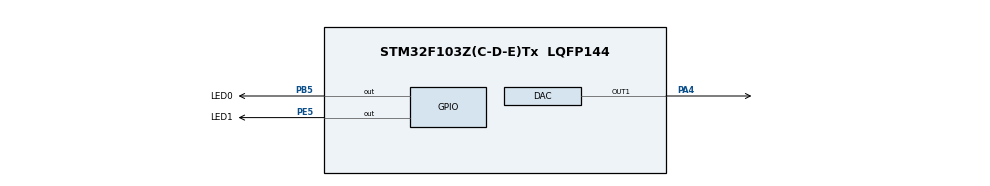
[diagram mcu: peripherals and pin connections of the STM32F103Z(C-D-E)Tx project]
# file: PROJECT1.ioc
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Mcu.Family=STM32F1
Mcu.Name=STM32F103Z(C-D-E)Tx
Mcu.Package=LQFP144
NVIC.PriorityGroup=NVIC_PRIORITYGROUP_4
PA4.Signal=COMP_DAC1_group
PB5.GPIO_Label=LED0
PB5.GPIO_ModeDefaultOutputPP=GPIO_MODE_OUTPUT_PP
PB5.GPIO_PuPd=GPIO_NOPULL
PB5.GPIO_Speed=GPIO_SPEED_FREQ_HIGH
PB5.PinState=GPIO_PIN_SET
PB5.Signal=GPIO_Output
PE5.GPIO_Label=LED1
PE5.GPIO_ModeDefaultOutputPP=GPIO_MODE_OUTPUT_PP
PE5.GPIO_PuPd=GPIO_NOPULL
PE5.GPIO_Speed=GPIO_SPEED_FREQ_HIGH
PE5.PinState=GPIO_PIN_SET
PE5.Signal=GPIO_Output
ProjectManager.HeapSize=0x200
ProjectManager.StackSize=0x400
ProjectManager.TargetToolchain=MDK-ARM V5.32
RCC.APB1Freq_Value=8000000
RCC.APB2Freq_Value=8000000
SH.COMP_DAC1_group.0=DAC_OUT1,DAC_OUT1
VP_SYS_VS_ND.Mode=No_Debug
board=custom

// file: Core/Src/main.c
/* USER CODE BEGIN Header */
/**
  ******************************************************************************
  * @file           : main.c
  * @brief          : Main program body
  ******************************************************************************
  * @attention
  *
  * Copyright (c) 2024 STMicroelectronics.
  * All rights reserved.
  *
  * This software is licensed under terms that can be found in the LICENSE file
  * in the root directory of this software component.
  * If no LICENSE file comes with this software, it is provided AS-IS.
  *
  ******************************************************************************
  */
/* USER CODE END Header */
#include "main.h"

DAC_HandleTypeDef hdac;

void SystemClock_Config(void);
static void MX_GPIO_Init(void);
static void MX_DAC_Init(void);

int main(void)
{

  /* MCU Configuration--------------------------------------------------------*/

  /* Reset of all peripherals, Initializes the Flash interface and the Systick. */
  HAL_Init();

  /* Configure the system clock */
  SystemClock_Config();

  /* Initialize all configured peripherals */
  MX_GPIO_Init();
  MX_DAC_Init();

  /* Infinite loop */
  /* USER CODE BEGIN WHILE */
  while (1)
  {
				HAL_GPIO_WritePin(LED0_GPIO_Port,LED0_Pin,GPIO_PIN_RESET);
				HAL_GPIO_WritePin(LED1_GPIO_Port,LED1_Pin,GPIO_PIN_RESET);

    /* USER CODE END WHILE */

  }
}

void SystemClock_Config(void)
{
  RCC_OscInitTypeDef RCC_OscInitStruct = {0};
  RCC_ClkInitTypeDef RCC_ClkInitStruct = {0};

  /** Initializes the RCC Oscillators according to the specified parameters
  * in the RCC_OscInitTypeDef structure.
  */
  RCC_OscInitStruct.OscillatorType = RCC_OSCILLATORTYPE_HSI;
  RCC_OscInitStruct.HSIState = RCC_HSI_ON;
  RCC_OscInitStruct.HSICalibrationValue = RCC_HSICALIBRATION_DEFAULT;
  RCC_OscInitStruct.PLL.PLLState = RCC_PLL_NONE;
  if (HAL_RCC_OscConfig(&RCC_OscInitStruct) != HAL_OK)
  {
    Error_Handler();
  }

  /** Initializes the CPU, AHB and APB buses clocks
  */
  RCC_ClkInitStruct.ClockType = RCC_CLOCKTYPE_HCLK|RCC_CLOCKTYPE_SYSCLK
                              |RCC_CLOCKTYPE_PCLK1|RCC_CLOCKTYPE_PCLK2;
  RCC_ClkInitStruct.SYSCLKSource = RCC_SYSCLKSOURCE_HSI;
  RCC_ClkInitStruct.AHBCLKDivider = RCC_SYSCLK_DIV1;
  RCC_ClkInitStruct.APB1CLKDivider = RCC_HCLK_DIV1;
  RCC_ClkInitStruct.APB2CLKDivider = RCC_HCLK_DIV1;

  if (HAL_RCC_ClockConfig(&RCC_ClkInitStruct, FLASH_LATENCY_0) != HAL_OK)
  {
    Error_Handler();
  }
}

static void MX_DAC_Init(void)
{

  DAC_ChannelConfTypeDef sConfig = {0};

  /** DAC Initialization
  */
  hdac.Instance = DAC;
  if (HAL_DAC_Init(&hdac) != HAL_OK)
  {
    Error_Handler();
  }

  /** DAC channel OUT1 config
  */
  sConfig.DAC_Trigger = DAC_TRIGGER_NONE;
  sConfig.DAC_OutputBuffer = DAC_OUTPUTBUFFER_ENABLE;
  if (HAL_DAC_ConfigChannel(&hdac, &sConfig, DAC_CHANNEL_1) != HAL_OK)
  {
    Error_Handler();
  }

}

static void MX_GPIO_Init(void)
{
  GPIO_InitTypeDef GPIO_InitStruct = {0};

  /* GPIO Ports Clock Enable */
  __HAL_RCC_GPIOE_CLK_ENABLE();
  __HAL_RCC_GPIOA_CLK_ENABLE();
  __HAL_RCC_GPIOB_CLK_ENABLE();

  /*Configure GPIO pin Output Level */
  HAL_GPIO_WritePin(LED1_GPIO_Port, LED1_Pin, GPIO_PIN_SET);

  /*Configure GPIO pin Output Level */
  HAL_GPIO_WritePin(LED1A1_GPIO_Port, LED1A1_Pin, GPIO_PIN_SET);

  /*Configure GPIO pin Output Level */
  HAL_GPIO_WritePin(LED0_GPIO_Port, LED0_Pin, GPIO_PIN_SET);

  /*Configure GPIO pin : LED1_Pin */
  GPIO_InitStruct.Pin = LED1_Pin;
  GPIO_InitStruct.Mode = GPIO_MODE_OUTPUT_PP;
  GPIO_InitStruct.Pull = GPIO_NOPULL;
  GPIO_InitStruct.Speed = GPIO_SPEED_FREQ_HIGH;
  HAL_GPIO_Init(LED1_GPIO_Port, &GPIO_InitStruct);

  /*Configure GPIO pin : LED1A1_Pin */
  GPIO_InitStruct.Pin = LED1A1_Pin;
  GPIO_InitStruct.Mode = GPIO_MODE_OUTPUT_PP;
  GPIO_InitStruct.Pull = GPIO_NOPULL;
  GPIO_InitStruct.Speed = GPIO_SPEED_FREQ_LOW;
  HAL_GPIO_Init(LED1A1_GPIO_Port, &GPIO_InitStruct);

  /*Configure GPIO pin : LED0_Pin */
  GPIO_InitStruct.Pin = LED0_Pin;
  GPIO_InitStruct.Mode = GPIO_MODE_OUTPUT_PP;
  GPIO_InitStruct.Pull = GPIO_NOPULL;
  GPIO_InitStruct.Speed = GPIO_SPEED_FREQ_HIGH;
  HAL_GPIO_Init(LED0_GPIO_Port, &GPIO_InitStruct);

}

void Error_Handler(void)
{
  __disable_irq();
  while (1)
  {
  }
}
